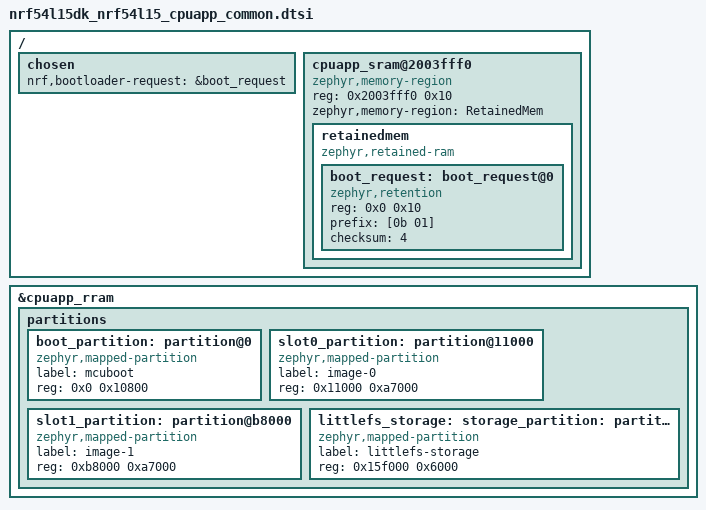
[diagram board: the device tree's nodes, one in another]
/*
 * Copyright (c) 2025 Nordic Semiconductor ASA
 *
 * SPDX-License-Identifier: LicenseRef-Nordic-5-Clause
 */

/ {
	chosen {
		nrf,bootloader-request = &boot_request;
	};
};

/ {
	cpuapp_sram@2003fff0 {
		compatible = "zephyr,memory-region", "mmio-sram";
		reg = <0x2003fff0 0x10>;
		zephyr,memory-region = "RetainedMem";
		status = "okay";

		retainedmem {
			compatible = "zephyr,retained-ram";
			status = "okay";
			#address-cells = <1>;
			#size-cells = <1>;

			boot_request: boot_request@0 {
				compatible = "zephyr,retention";
				status = "okay";
				reg = <0x0 0x10>;
				prefix = [0b 01];
				checksum = <4>;
			};
		};
	};
};

/* Pin the flash map to the NCS v3.2 layout so the update image is accepted by
 * an NCS v3.2 MCUboot: slot0 ends at 0xb8000, placing slot1 at 0xb8000. The
 * MCUboot image trailer lives at the end of each slot, so the slot ends must
 * match the released layout.
 */
/delete-node/ &boot_partition;
/delete-node/ &slot0_partition;
/delete-node/ &slot1_partition;
/delete-node/ &storage_partition;

&cpuapp_rram {
	partitions {
		boot_partition: partition@0 {
			compatible = "zephyr,mapped-partition";
			label = "mcuboot";
			reg = <0x0 0x10800>;
		};

		slot0_partition: partition@11000 {
			compatible = "zephyr,mapped-partition";
			label = "image-0";
			reg = <0x11000 0xa7000>;
		};

		slot1_partition: partition@b8000 {
			compatible = "zephyr,mapped-partition";
			label = "image-1";
			reg = <0xb8000 0xa7000>;
		};

		littlefs_storage: storage_partition: partition@15f000 {
			compatible = "zephyr,mapped-partition";
			label = "littlefs-storage";
			reg = <0x15f000 0x6000>;
		};
	};
};
